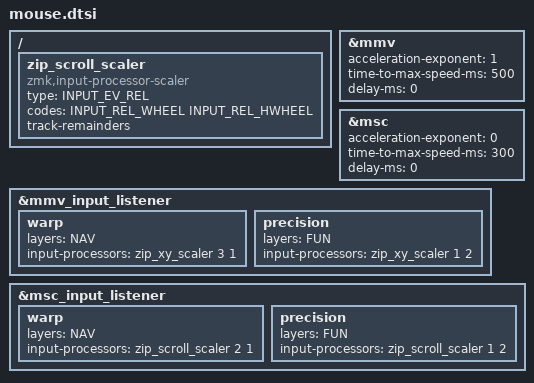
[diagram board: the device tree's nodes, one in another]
/*
*
* Copyright (c) 2025 Ryan Luckie
* SPDX-License-Identifier: MIT
*
*/

#include <dt-bindings/zmk/pointing.h>
#include <input/processors.dtsi>
#include <zephyr/dt-bindings/input/input-event-codes.h>

// Based on @caksoylar's config, defaults in comments
&mmv {
  acceleration-exponent = <1>;          // 1
  time-to-max-speed-ms = <500>;         // 300
  delay-ms = <0>;                       // 0
};

&msc {
  acceleration-exponent = <0>;          // 0
  time-to-max-speed-ms = <300>;         // 300
  delay-ms = <0>;                       // 0
};

&mmv_input_listener {
  warp {
    layers = <NAV>;
    input-processors = <&zip_xy_scaler 3 1>;
  };
  precision {
    layers = <FUN>;
    input-processors = <&zip_xy_scaler 1 2>;
  };
};

/ {
  zip_scroll_scaler: zip_scroll_scaler {
    compatible = "zmk,input-processor-scaler";
    #input-processor-cells = <2>;
    type = <INPUT_EV_REL>;
    codes = <INPUT_REL_WHEEL INPUT_REL_HWHEEL>;
    track-remainders;
  };
};

&msc_input_listener {
  warp {
    layers = <NAV>;
    input-processors = <&zip_scroll_scaler 2 1>;
  };
  precision {
    layers = <FUN>;
    input-processors = <&zip_scroll_scaler 1 2>;
  };
};
